AUTOSAR XML (schema 4-0-3)
package /ComponentTypes
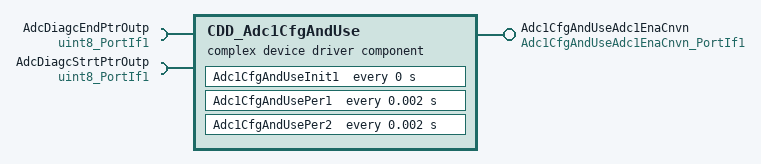
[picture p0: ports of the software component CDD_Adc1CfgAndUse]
  complex device driver sw component type CDD_Adc1CfgAndUse
    provide port Adc1CfgAndUseAdc1EnaCnvn: server-com-spec{operation=Oper, queue-length=1}, provided-interface=Adc1CfgAndUseAdc1EnaCnvn_PortIf1
    require port AdcDiagcEndPtrOutp: nonqueued-receiver-com-spec{data-element=Val, filter=data-filter-type=ALWAYS, init-value=23}, required-interface=uint8_PortIf1
    require port AdcDiagcStrtPtrOutp: nonqueued-receiver-com-spec{data-element=Val, filter=data-filter-type=ALWAYS, init-value=21}, required-interface=uint8_PortIf1
    behavior CDD_Adc1CfgAndUse_InternalBehavior
      ar-typed-per-instance-memorys:
        data Adc1DiagcEndPtr: sw-calibration-access=READ-ONLY, type=uint8
        data Adc1DiagcStrtPtr: sw-calibration-access=READ-ONLY, type=uint8
      operation invoked event OIT_Adc1CfgAndUseAdc1EnaCnvn_Oper_Adc1CfgAndUseAdc1EnaCnvn_Oper: start-on-event=Adc1CfgAndUseAdc1EnaCnvn_Oper, operation=Adc1CfgAndUseAdc1EnaCnvn.Oper
      timing event CDD_Adc1CfgAndUse_InitEvent: start-on-event=Adc1CfgAndUseInit1, period=0
      timing event TMT_Adc1CfgAndUsePer1: start-on-event=Adc1CfgAndUsePer1, period=0.002
      timing event TMT_Adc1CfgAndUsePer2: start-on-event=Adc1CfgAndUsePer2, period=0.002
      4 x runnable:
        Adc1CfgAndUseAdc1EnaCnvn_Oper
        Adc1CfgAndUseInit1
        Adc1CfgAndUsePer1
        Adc1CfgAndUsePer2
          data-receive-point-by-arguments:
            access REC_AdcDiagcEndPtrOutp_Val: accessed-variable=AdcDiagcEndPtrOutp.Val
            access REC_AdcDiagcStrtPtrOutp_Val: accessed-variable=AdcDiagcStrtPtrOutp.Val
  swc implementation CDD_Adc1CfgAndUse_Implementation: behavior=CDD_Adc1CfgAndUse_InternalBehavior
    code-descriptors:
      code Default: artifact-descriptors=autosar-engineering-object={short-label=Default, category=SWSRC}
